# AT32UC3A4256S device description
Architecture: AVR32_UC3; Family: AVR UC3
Registers are 32-bit, read-write, reset 0x0 unless marked. A register's access mark holds for its fields unless they carry their own. Offsets are from the block's base; [hi:lo] are bit positions; {n}, {i} and the like mark numbered series.

## MCI — Mulitmedia Card Interface
Instances: MCI 0xfffe4000
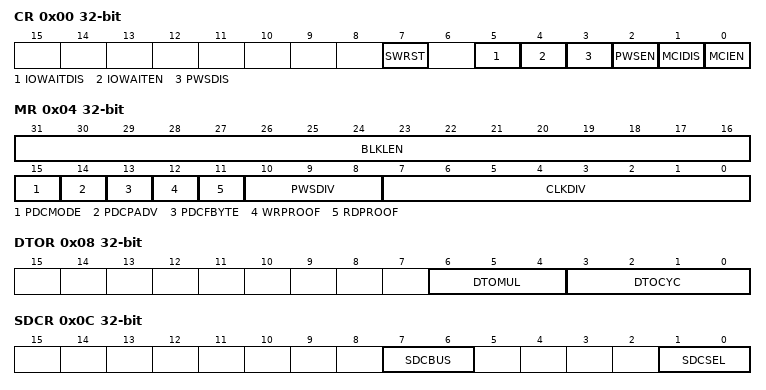
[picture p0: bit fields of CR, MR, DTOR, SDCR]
0x00 CR wo reset not defined — Control Register
  [7] SWRST — Software reset
  [5] IOWAITDIS — SDIO Read Wait Disable
  [4] IOWAITEN — SDIO Read Wait Enable
  [3] PWSDIS — Power Save Mode Disable
  [2] PWSEN — Power Save Mode Enable
  [1] MCIDIS — MultiMedia Interface Disable
  [0] MCIEN — MultiMedia Interface Enable
0x04 MR — Mode Register
  [31:16] BLKLEN — Data Block Length
  [15] PDCMODE — PDC Oriented Mode
  [14] PDCPADV — PDC Padding Value
  [13] PDCFBYTE — PDC Force Byte Transfer
  [12] WRPROOF — Write Proof Enable
  [11] RDPROOF — Read Proof Enable
  [10:8] PWSDIV — Power Saving Divider
  [7:0] CLKDIV — Clock Divider
0x08 DTOR — Data Timeout Register
  [6:4] DTOMUL — Data Timeout Multiplier
    0=1_CYCLE; 1=16_CYCLES; 2=128_CYCLES; 3=256_CYCLES; 4=1024_CYCLES; 5=4096_CYCLES; 6=65536_CYCLES; 7=1048576_CYCLES
  [3:0] DTOCYC — Data Timeout Cycle Number
0x0C SDCR reset not defined — SD Card Register
  [7:6] SDCBUS — SD Card Bus Width
  [1:0] SDCSEL — SC Card Selector
0x10 ARGR — Argument Register
  [31:0] ARG — Command Argument
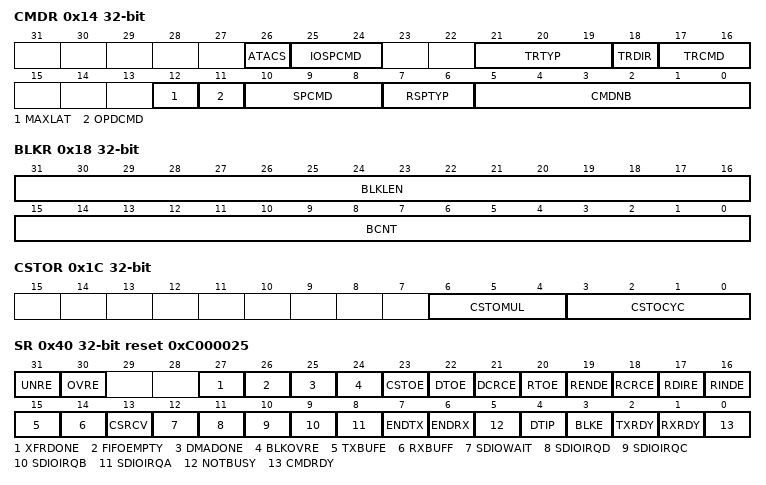
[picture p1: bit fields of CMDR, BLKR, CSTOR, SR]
0x14 CMDR wo reset not defined — This register is write-protected while CMDRDY is 0 in SR. This means that the current command execution cannot be interrupted or modified.
  [26] ATACS — ATA with command completion signal
  [25:24] IOSPCMD — SDIO Special Command
  [21:19] TRTYP — Transfer Type
    0=BLOCK; 1=MULTI_BLOCK; 2=STREAM
  [18] TRDIR — Transfer Direction
  [17:16] TRCMD — Transfer Command
    0=NO_TRANS; 1=START_TRANS; 2=STOP_TRANS
  [12] MAXLAT — Maximum Latency for Command to Respond
  [11] OPDCMD — Open Drain Command
  [10:8] SPCMD — Special CMD
    0=NO_SPEC_CMD; 1=INIT_CMD; 2=SYNC_CMD; 4=INT_CMD; 5=INT_RESP
  [7:6] RSPTYP — Response Type
    0=NO_RESP; 1=48_BIT_RESP; 2=136_BIT_RESP
  [5:0] CMDNB — Command Number
0x18 BLKR — Block Register
  [31:16] BLKLEN — Data Block Length
  [15:0] BCNT — MMC/SDIO Block Count - SDIO Byte Count
0x1C CSTOR — Completion Signal Timeout Register
  [6:4] CSTOMUL — Completion Signal Timeout Multiplier
  [3:0] CSTOCYC — Completion Signal Timeout Cycle Number
0x20 RSPR ro — Response Register
  [31:0] RSP — Response
{0x20+4i} RSPR{i} ro (i=1..3) — Response Register
  [31:0] RSP — Response
0x30 RDR ro — Receive Data Register
  [31:0] DATA
0x34 TDR wo reset not defined — Transmit Data Register
  [31:0] DATA
0x40 SR ro reset 0xC000025 — Status Register
  [31] UNRE — Underrun Status
  [30] OVRE — Overrun Status
  [27] XFRDONE — Transfer Done flag
  [26] FIFOEMPTY — FIFO empty flag
  [25] DMADONE — DMA Transfer done
  [24] BLKOVRE — DMA Block Overrun Error
  [23] CSTOE — Completion Signal Time-out Error
  [22] DTOE — Data Timeout Error Status
  [21] DCRCE — Data CRC Error Status
  [20] RTOE — Response Timeout Error Status
  [19] RENDE — Response End Bit Error Status
  [18] RCRCE — Response CRC Error Status
  [17] RDIRE — Response Direction Error Status
  [16] RINDE — Response Index Error Status
  [15] TXBUFE — TX Buffer Empty Status
  [14] RXBUFF — RX Buffer Full Status
  [13] CSRCV — CE-ATA Completion Signal Received
  [12] SDIOWAIT — SDIO Read Wait operation status
  [11] SDIOIRQD — SDIO Interrupt for Slot D
  [10] SDIOIRQC — SDIO Interrupt for Slot C
  [9] SDIOIRQB — SDIO Interrupt for Slot B
  [8] SDIOIRQA — SDIO Interrupt for Slot A
  [7] ENDTX — End of TX Buffer Status
  [6] ENDRX — End of RX Buffer Status
  [5] NOTBUSY — Data Line Not Busy Status
  [4] DTIP — Data Transfer in Progress Status
  [3] BLKE — Data Block Transfer Ended Status
  [2] TXRDY — TX Ready Status
  [1] RXRDY — RX Ready Status
  [0] CMDRDY — Command Ready Status
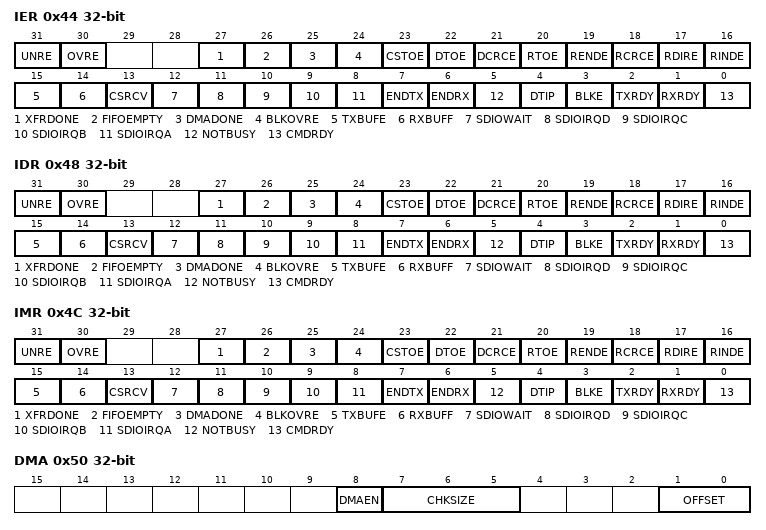
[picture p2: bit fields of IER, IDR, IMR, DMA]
0x44 IER wo reset not defined — Interrupt Enable Register
  [31] UNRE — Underrun Error Interrupt
  [30] OVRE — Overrun Error Interrupt
  [27] XFRDONE — Transfer Done Interrupt enable
  [26] FIFOEMPTY — FIFO empty Interrupt enable
  [25] DMADONE — DMA Transfer completed Interrupt Enable
  [24] BLKOVRE — DMA Block Overrun Error Interrupt Enable
  [23] CSTOE — Completion Signal Timeout Error Interrupt Enable
  [22] DTOE — Data Timeout Error Interrupt
  [21] DCRCE — Data CRC Error Interrupt
  [20] RTOE — Response Timeout Error Interrupt
  [19] RENDE — Response End Bit Error Interrupt
  [18] RCRCE — Response CRC Error Interrupt
  [17] RDIRE — Response Direction Error Interrupt
  [16] RINDE — Response Index Error Interrupt
  [15] TXBUFE — TX Buffer Empty Interrupt
  [14] RXBUFF — RX Buffer Full Interrupt
  [13] CSRCV — Completion Signal Received Interrupt Enable
  [12] SDIOWAIT — SDIO wait Interrupt Enable
  [11] SDIOIRQD — SDIO Interrupt for Slot D Interrupt Enable
  [10] SDIOIRQC — SDIO Interrupt for Slot C Interrupt Enable
  [9] SDIOIRQB — SDIO Interrupt for Slot B Interrupt Enable
  [8] SDIOIRQA — SDIO Interrupt for Slot A Interrupt Enable
  [7] ENDTX — End of TX Buffer Interrupt
  [6] ENDRX — End of RX Buffer Interrupt
  [5] NOTBUSY — Data Not Busy Interrupt
  [4] DTIP — Data Transfer in Progress Interrupt
  [3] BLKE — Data Block Ended Interrupt
  [2] TXRDY — TX Ready Interrupt
  [1] RXRDY — RX Ready Interrupt
  [0] CMDRDY — Command Ready Interrupt
0x48 IDR wo reset not defined — Interrupt Disable Register
  [31] UNRE — Underrun Interrupt
  [30] OVRE — Overrun Interrupt
  [27] XFRDONE — Transfer Done Interrupt Disable
  [26] FIFOEMPTY — FIFO empty Interrupt Disable
  [25] DMADONE — DMA Transfer completed Interrupt Disable
  [24] BLKOVRE — DMA Block Overrun Error Interrupt Disable
  [23] CSTOE — Completion Signal Time out Error Interrupt Disable
  [22] DTOE — Data Timeout Error Interrupt
  [21] DCRCE — Data CRC Error Interrut
  [20] RTOE — Response Timeout Error Interrupt
  [19] RENDE — Response End Bit Error Interrupt
  [18] RCRCE — Response CRC Error Interrupt
  [17] RDIRE — Response Direction Error Interrupt
  [16] RINDE — Response Index Error Interrupt
  [15] TXBUFE — TX Buffer Empty Interrupt
  [14] RXBUFF — RX Buffer Full Interrupt
  [13] CSRCV — Completion Signal received interrupt disable
  [12] SDIOWAIT — SDIO wait interrupt disable
  [11] SDIOIRQD — SDIO Interrupt for Slot D Interrupt Disable
  [10] SDIOIRQC — SDIO Interrupt for Slot C Interrupt Disable
  [9] SDIOIRQB — SDIO Interrupt for Slot B Interrupt Disable
  [8] SDIOIRQA — SDIO Interrupt for Slot A Interrupt Disable
  [7] ENDTX — End of TX Buffer Interrupt
  [6] ENDRX — End of RX Buffer Interrupt
  [5] NOTBUSY — Data Not Busy Interrupt
  [4] DTIP — Data Transfer in Progress Interrupt
  [3] BLKE — Data Block Ended Interrupt
  [2] TXRDY — TX Ready Interrupt
  [1] RXRDY — RX Ready Interrupt
  [0] CMDRDY — Command Ready Interrupt
0x4C IMR ro — This register shows which interrupt is masked.
  [31] UNRE — Underrun Interrupt
  [30] OVRE — Overrun Interrupt
  [27] XFRDONE — Transfer Done Interrupt Mask
  [26] FIFOEMPTY — FIFO Empty Interrupt Mask
  [25] DMADONE — DMA Transfer Completed Interrupt Mask
  [24] BLKOVRE — DMA Block Overrun Error Interrupt Mask
  [23] CSTOE — Completion Signal Time-out Error Interrupt Mask
  [22] DTOE — Data Timeout Error Interrupt
  [21] DCRCE — Data CRC Error Interrupt
  [20] RTOE — Response Timeout Error Interrupt
  [19] RENDE — Response End Bit Error Interrupt
  [18] RCRCE — Response CRC Error Interrupt
  [17] RDIRE — Response Direction Error Interrupt
  [16] RINDE — Response Index Error Interrupt
  [15] TXBUFE — TX Buffer Empty Interrupt
  [14] RXBUFF — RX Buffer Full Interrupt
  [13] CSRCV — Completion Signal Received Interrupt Mask
  [12] SDIOWAIT — SDIO wait Interrupt Mask
  [11] SDIOIRQD — SDIO Interrupt for Slot D Interrupt Mask
  [10] SDIOIRQC — SDIO Interrupt for Slot C Interrupt Mask
  [9] SDIOIRQB — SDIO Interrupt for Slot B Interrupt Mask
  [8] SDIOIRQA — SDIO Interrupt for Slot A Interrupt Mask
  [7] ENDTX — End of TX Buffer Interrupt
  [6] ENDRX — End of RX Buffer Interrupt
  [5] NOTBUSY — Data Not Busy Interrupt
  [4] DTIP — Data Transfer in Progress Status
  [3] BLKE — Data Block Ended Interrupt
  [2] TXRDY — TX Ready Interrupt
  [1] RXRDY — RX Ready Interrupt
  [0] CMDRDY — Command Ready Interrupt
0x50 DMA — DMA Configuration Register
  [8] DMAEN — DMA hardware handshaking Enable
  [7:5] CHKSIZE — DMA channel read and write Chunk Size
  [1:0] OFFSET — DMA Write buffer offset
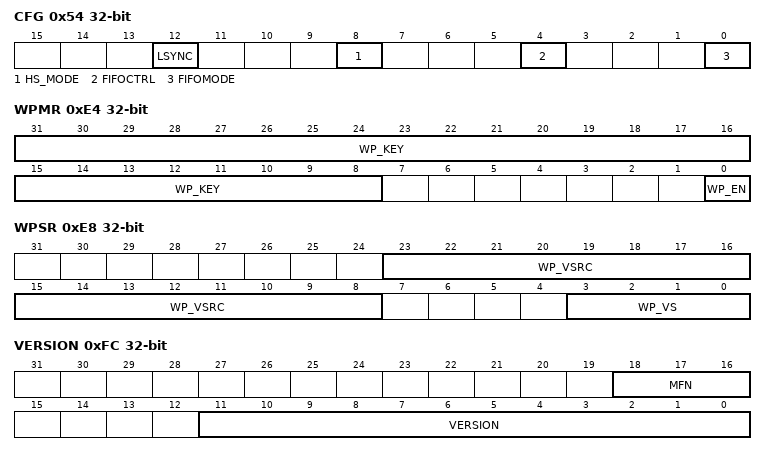
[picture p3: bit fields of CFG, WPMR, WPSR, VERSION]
0x54 CFG — Configuration Register
  [12] LSYNC — Synchronize on the last block
  [8] HS_MODE — High Speed mode
  [4] FIFOCTRL — Flow Error flag reset control mode
  [0] FIFOMODE — MCI Internal FIFO control mode
0xE4 WPMR reset not defined — Write Protect Mode Register
  [31:8] WP_KEY — Write Protection Enable
  [0] WP_EN — Write Protection Key password
0xE8 WPSR ro reset not defined — Write Protect Status Register
  [23:8] WP_VSRC — Write Protection Violation SouRCe
  [3:0] WP_VS — Write Protection Violation Status
0xFC VERSION ro reset not defined
  [18:16] MFN — Reserved.
  [11:0] VERSION — Reserved.
0x200 FIFO — FIFO memory aperture
  [31:0] DATA — Data to Read or Data to Write
